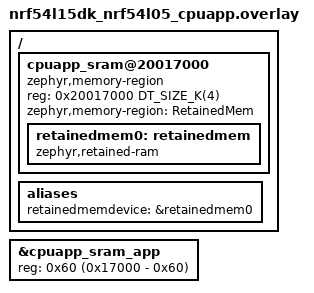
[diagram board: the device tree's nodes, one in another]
/ {
	cpuapp_sram@20017000 {
		compatible = "zephyr,memory-region", "mmio-sram";
		reg = <0x20017000 DT_SIZE_K(4)>;
		zephyr,memory-region = "RetainedMem";
		status = "okay";

		retainedmem0: retainedmem {
			compatible = "zephyr,retained-ram";
			status = "okay";
		};
	};

	aliases {
		retainedmemdevice = &retainedmem0;
	};
};

&cpuapp_sram_app {
	/* Shrink SRAM size to avoid overlap with retained memory region:
	 * 96 - 4 = 92KB = 0x17000
	 */
	reg = <0x60 (0x17000 - 0x60)>;
};
